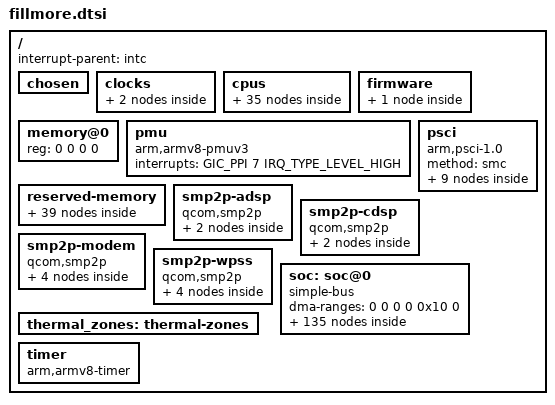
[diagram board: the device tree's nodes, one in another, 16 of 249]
// SPDX-License-Identifier: GPL-2.0-only
/*
 * Copyright (c) 2026, Aelin Reidel <aelin@mainlining.org>
 */

#include <dt-bindings/clock/qcom,dsi-phy-28nm.h>
#include <dt-bindings/clock/qcom,fillmore-dispcc.h>
#include <dt-bindings/clock/qcom,fillmore-gcc.h>
#include <dt-bindings/clock/qcom,fillmore-gpucc.h>
#include <dt-bindings/clock/qcom,rpmh.h>
#include <dt-bindings/dma/qcom-gpi.h>
#include <dt-bindings/firmware/qcom,scm.h>
#include <dt-bindings/gpio/gpio.h>
#include <dt-bindings/interrupt-controller/arm-gic.h>
#include <dt-bindings/mailbox/qcom-ipcc.h>
#include <dt-bindings/power/qcom,rpmhpd.h>
#include <dt-bindings/soc/qcom,rpmh-rsc.h>

/ {
	interrupt-parent = <&intc>;

	#address-cells = <2>;
	#size-cells = <2>;

	chosen { };

	clocks {
		xo_board: xo_board {
			compatible = "fixed-clock";
			clock-frequency = <76800000>;
			#clock-cells = <0>;
		};

		sleep_clk: sleep_clk {
			compatible = "fixed-clock";
			clock-frequency = <32000>;
			#clock-cells = <0>;
		};
	};

	cpus {
		#address-cells = <2>;
		#size-cells = <0>;

		cpu0: cpu@0 {
			device_type = "cpu";
			compatible = "qcom,kryo780";
			reg = <0x0 0x0>;

			clocks = <&cpufreq_hw 0>;

			power-domains = <&cpu_pd0>;
			power-domain-names = "psci";

			enable-method = "psci";
			next-level-cache = <&l2_0>;
			capacity-dmips-mhz = <1024>;
			dynamic-power-coefficient = <100>;

			qcom,freq-domain = <&cpufreq_hw 0>;

			#cooling-cells = <2>;

			l2_0: l2-cache {
				compatible = "cache";
				cache-level = <2>;
				cache-unified;
				next-level-cache = <&l3_0>;

				l3_0: l3-cache {
					compatible = "cache";
					cache-level = <3>;
					cache-unified;
				};
			};
		};

		cpu1: cpu@100 {
			device_type = "cpu";
			compatible = "qcom,kryo780";
			reg = <0x0 0x100>;

			clocks = <&cpufreq_hw 0>;

			power-domains = <&cpu_pd1>;
			power-domain-names = "psci";

			enable-method = "psci";
			next-level-cache = <&l2_0>;
			capacity-dmips-mhz = <1024>;
			dynamic-power-coefficient = <100>;

			qcom,freq-domain = <&cpufreq_hw 0>;

			#cooling-cells = <2>;
		};

		cpu2: cpu@200 {
			device_type = "cpu";
			compatible = "qcom,kryo780";
			reg = <0x0 0x200>;

			clocks = <&cpufreq_hw 0>;

			power-domains = <&cpu_pd2>;
			power-domain-names = "psci";

			enable-method = "psci";
			next-level-cache = <&l2_2>;
			capacity-dmips-mhz = <1024>;
			dynamic-power-coefficient = <100>;

			qcom,freq-domain = <&cpufreq_hw 0>;

			#cooling-cells = <2>;

			l2_2: l2-cache {
				compatible = "cache";
				cache-level = <2>;
				cache-unified;
				next-level-cache = <&l3_0>;
			};
		};

		cpu3: cpu@300 {
			device_type = "cpu";
			compatible = "qcom,kryo780";
			reg = <0x0 0x300>;

			clocks = <&cpufreq_hw 0>;

			power-domains = <&cpu_pd3>;
			power-domain-names = "psci";

			enable-method = "psci";
			next-level-cache = <&l2_2>;
			capacity-dmips-mhz = <1024>;
			dynamic-power-coefficient = <100>;

			qcom,freq-domain = <&cpufreq_hw 0>;

			#cooling-cells = <2>;
		};

		cpu4: cpu@400 {
			device_type = "cpu";
			compatible = "qcom,kryo780";
			reg = <0x0 0x400>;

			clocks = <&cpufreq_hw 1>;

			power-domains = <&cpu_pd4>;
			power-domain-names = "psci";

			enable-method = "psci";
			next-level-cache = <&l2_4>;
			capacity-dmips-mhz = <2253>;
			dynamic-power-coefficient = <260>;

			qcom,freq-domain = <&cpufreq_hw 1>;

			#cooling-cells = <2>;

			l2_4: l2-cache {
				compatible = "cache";
				cache-level = <2>;
				cache-unified;
				next-level-cache = <&l3_0>;
			};
		};

		cpu5: cpu@500 {
			device_type = "cpu";
			compatible = "qcom,kryo780";
			reg = <0x0 0x500>;

			clocks = <&cpufreq_hw 1>;

			power-domains = <&cpu_pd5>;
			power-domain-names = "psci";

			enable-method = "psci";
			next-level-cache = <&l2_5>;
			capacity-dmips-mhz = <2253>;
			dynamic-power-coefficient = <260>;

			qcom,freq-domain = <&cpufreq_hw 1>;

			#cooling-cells = <2>;

			l2_5: l2-cache {
				compatible = "cache";
				cache-level = <2>;
				cache-unified;
				next-level-cache = <&l3_0>;
			};
		};

		cpu6: cpu@600 {
			device_type = "cpu";
			compatible = "qcom,kryo780";
			reg = <0x0 0x600>;

			clocks = <&cpufreq_hw 1>;

			power-domains = <&cpu_pd6>;
			power-domain-names = "psci";

			enable-method = "psci";
			next-level-cache = <&l2_6>;
			capacity-dmips-mhz = <2253>;
			dynamic-power-coefficient = <260>;

			qcom,freq-domain = <&cpufreq_hw 1>;

			#cooling-cells = <2>;

			l2_6: l2-cache {
				compatible = "cache";
				cache-level = <2>;
				cache-unified;
				next-level-cache = <&l3_0>;
			};
		};

		cpu7: cpu@700 {
			device_type = "cpu";
			compatible = "qcom,kryo780";
			reg = <0x0 0x700>;

			clocks = <&cpufreq_hw 2>;

			power-domains = <&cpu_pd7>;
			power-domain-names = "psci";

			enable-method = "psci";
			next-level-cache = <&l2_7>;
			capacity-dmips-mhz = <2386>;
			dynamic-power-coefficient = <396>;

			qcom,freq-domain = <&cpufreq_hw 2>;

			#cooling-cells = <2>;

			l2_7: l2-cache {
				compatible = "cache";
				cache-level = <2>;
				cache-unified;
				next-level-cache = <&l3_0>;
			};
		};

		cpu-map {
			cluster0 {
				core0 {
					cpu = <&cpu0>;
				};

				core1 {
					cpu = <&cpu1>;
				};

				core2 {
					cpu = <&cpu2>;
				};

				core3 {
					cpu = <&cpu3>;
				};
			};

			cluster1 {
				core0 {
					cpu = <&cpu4>;
				};

				core1 {
					cpu = <&cpu5>;
				};

				core2 {
					cpu = <&cpu6>;
				};
			};

			cluster2 {
				core0 {
					cpu = <&cpu7>;
				};
			};
		};

		idle-states {
			entry-method = "psci";

			silver_cpu_sleep_0: cpu-sleep-0-0 {
				compatible = "arm,idle-state";
				idle-state-name = "pc";
				arm,psci-suspend-param = <0x40000003>;
				entry-latency-us = <350>;
				exit-latency-us = <900>;
				min-residency-us = <1774>;
				local-timer-stop;
			};

			silver_cpu_sleep_1: cpu-sleep-0-1 {
				compatible = "arm,idle-state";
				idle-state-name = "silver-rail-power-collapse";
				arm,psci-suspend-param = <0x40000004>;
				entry-latency-us = <800>;
				exit-latency-us = <750>;
				min-residency-us = <4090>;
				local-timer-stop;
			};

			gold_cpu_sleep_0: cpu-sleep-1-0 {
				compatible = "arm,idle-state";
				idle-state-name = "gold-power-collapse";
				arm,psci-suspend-param = <0x40000003>;
				entry-latency-us = <400>;
				exit-latency-us = <1550>;
				min-residency-us = <2207>;
				local-timer-stop;
			};

			gold_cpu_sleep_1: cpu-sleep-1-1 {
				compatible = "arm,idle-state";
				idle-state-name = "gold-rail-power-collapse";
				arm,psci-suspend-param = <0x40000004>;
				entry-latency-us = <600>;
				exit-latency-us = <1550>;
				min-residency-us = <4791>;
				local-timer-stop;
			};
		};

		domain-idle-states {
			cluster_sleep_0: cluster-sleep-0 {
				compatible = "domain-idle-state";
				arm,psci-suspend-param = <0x41000044>;
				entry-latency-us = <1050>;
				exit-latency-us = <2500>;
				min-residency-us = <5309>;
			};

			cluster_sleep_1: cluster-sleep-1 {
				compatible = "domain-idle-state";
				arm,psci-suspend-param = <0x4100b344>;
				entry-latency-us = <2700>;
				exit-latency-us = <3500>;
				min-residency-us = <13959>;
			};
		};
	};

	firmware {
		scm: scm {
			compatible = "qcom,scm-fillmore", "qcom,scm";
			qcom,dload-mode = <&tcsr 0x13000>;
		};
	};

	memory@0 {
		device_type = "memory";
		/* We expect the bootloader to fill in the size */
		reg = <0 0 0 0>;
	};

	pmu {
		compatible = "arm,armv8-pmuv3";
		interrupts = <GIC_PPI 7 IRQ_TYPE_LEVEL_HIGH>;
	};

	psci {
		compatible = "arm,psci-1.0";
		method = "smc";

		cpu_pd0: power-domain-cpu0 {
			#power-domain-cells = <0>;
			power-domains = <&cluster_pd>;
			domain-idle-states = <&silver_cpu_sleep_0>, <&silver_cpu_sleep_1>;
		};

		cpu_pd1: power-domain-cpu1 {
			#power-domain-cells = <0>;
			power-domains = <&cluster_pd>;
			domain-idle-states = <&silver_cpu_sleep_0>, <&silver_cpu_sleep_1>;
		};

		cpu_pd2: power-domain-cpu2 {
			#power-domain-cells = <0>;
			power-domains = <&cluster_pd>;
			domain-idle-states = <&silver_cpu_sleep_0>, <&silver_cpu_sleep_1>;
		};

		cpu_pd3: power-domain-cpu3 {
			#power-domain-cells = <0>;
			power-domains = <&cluster_pd>;
			domain-idle-states = <&silver_cpu_sleep_0>, <&silver_cpu_sleep_1>;
		};

		cpu_pd4: power-domain-cpu4 {
			#power-domain-cells = <0>;
			power-domains = <&cluster_pd>;
			domain-idle-states = <&gold_cpu_sleep_0>, <&gold_cpu_sleep_1>;
		};

		cpu_pd5: power-domain-cpu5 {
			#power-domain-cells = <0>;
			power-domains = <&cluster_pd>;
			domain-idle-states = <&gold_cpu_sleep_0>, <&gold_cpu_sleep_1>;
		};

		cpu_pd6: power-domain-cpu6 {
			#power-domain-cells = <0>;
			power-domains = <&cluster_pd>;
			domain-idle-states = <&gold_cpu_sleep_0>, <&gold_cpu_sleep_1>;
		};

		cpu_pd7: power-domain-cpu7 {
			#power-domain-cells = <0>;
			power-domains = <&cluster_pd>;
			domain-idle-states = <&gold_cpu_sleep_0>, <&gold_cpu_sleep_1>;
		};

		cluster_pd: power-domain-cluster {
			#power-domain-cells = <0>;
			domain-idle-states = <&cluster_sleep_0>, <&cluster_sleep_1>;
		};
	};

	reserved-memory {
		#address-cells = <2>;
		#size-cells = <2>;
		ranges;

		hyp_mem: hyp-region@80000000 {
			reg = <0x0 0x80000000 0x0 0x600000>;
			no-map;
		};

		xbl_dtlog_mem: xbl-dtlog-region@80600000 {
			reg = <0x0 0x80600000 0x0 0x40000>;
			no-map;
		};

		xbl_ramdump_mem: xbl-ramdump-region@80640000 {
			reg = <0x0 0x80640000 0x0 0x1c0000>;
			no-map;
		};

		aop_image_mem: aop-image-region@80800000 {
			reg = <0x0 0x80800000 0x0 0x60000>;
			no-map;
		};

		aop_cmd_db_mem: aop-cmd-db-region@80860000 {
			compatible = "qcom,cmd-db";
			reg = <0x0 0x80860000 0x0 0x20000>;
			no-map;
		};

		aop_config_mem: aop-config-region@80880000 {
			reg = <0x0 0x80880000 0x0 0x20000>;
			no-map;
		};

		tme_crash_dump_mem: tme-crash-dump-region@808a0000 {
			reg = <0x0 0x808a0000 0x0 0x40000>;
			no-map;
		};

		tme_log_mem: tme-log-region@808e0000 {
			reg = <0x0 0x808e0000 0x0 0x4000>;
			no-map;
		};

		uefi_log_mem: uefi-log-mem@808e4000 {
			reg = <0x0 0x808e4000 0x0 0x10000>;
			no-map;
		};

		smem_mem: smem-region@80900000 {
			compatible = "qcom,smem";
			reg = <0x0 0x80900000 0x0 0x200000>;
			hwlocks = <&tcsr_mutex 3>;
			no-map;
		};

		cpucp_fw_mem: cpucp-fw-region@80b00000 {
			reg = <0x0 0x80b00000 0x0 0x100000>;
			no-map;
		};

		cdsp_secure_heap_mem: cdsp-secure-heap-region@80c00000 {
			reg = <0x0 0x80c00000 0x0 0x1e00000>;
			no-map;
		};

		wlan_fw_mem: wlan-fw-region@82a00000 {
			reg = <0x0 0x82a00000 0x0 0xc00000>;
			no-map;
		};

		camera_mem: camera-region@84e00000 {
			reg = <0x0 0x84e00000 0x0 0x500000>;
			no-map;
		};

		wpss_mem: wpss-region@85300000 {
			reg = <0x0 0x85300000 0x0 0x1900000>;
			no-map;
		};

		video_mem: video-region@86c00000 {
			reg = <0x0 0x86c00000 0x0 0x700000>;
			no-map;
		};

		adsp_mem: adsp-region@87300000 {
			reg = <0x0 0x87300000 0x0 0x2800000>;
			no-map;
		};

		cdsp_mem: cdsp-region@89b00000 {
			reg = <0x0 0x89b00000 0x0 0x2000000>;
			no-map;
		};

		ipa_fw_mem: ipa-fw-region@8bb00000 {
			reg = <0x0 0x8bb00000 0x0 0x10000>;
			no-map;
		};

		ipa_gsi_mem: ipa-gsi-region@8bb10000 {
			reg = <0x0 0x8bb10000 0x0 0xa000>;
			no-map;
		};

		gpu_microcode_mem: gpu-microcode-region@8bb1a000 {
			reg = <0x0 0x8bb1a000 0x0 0x2000>;
			no-map;
		};

		mpss_mem: mpss-region@8bc00000 {
			reg = <0x0 0x8bc00000 0x0 0x13200000>;
			no-map;
		};

		cvp_mem: cvp-region@9ee00000 {
			reg = <0x0 0x9ee00000 0x0 0x500000>;
			no-map;
		};

		xbl_sc_mem: xbl-sc-region@a6e00000 {
			reg = <0x0 0xa6e00000 0x0 0x40000>;
			no-map;
		};

		global_sync_mem: global-sync-region@a6f00000 {
			reg = <0x0 0xa6f00000 0x0 0x100000>;
			no-map;
		};

		oem_vm_mem: oem-vm-region@bb000000 {
			reg = <0x0 0xbb000000 0x0 0x5000000>;
			no-map;
		};

		mte_mem: mte-region@c0000000 {
			reg = <0x0 0xc0000000 0x0 0x20000000>;
			no-map;
		};

		qheebsp_reserved_mem: qheebsp-reserved-region@e0000000 {
			reg = <0x0 0xe0000000 0x0 0x600000>;
			no-map;
		};

		cpusys_vm_mem: cpusys-vm-region@e0600000 {
			reg = <0x0 0xe0600000 0x0 0x400000>;
			no-map;
		};

		trust_ui_vm_mem: trust-ui-vm-region@e0b00000 {
			reg = <0x0 0xe0b00000 0x0 0x4af3000>;
			no-map;
		};

		trust_ui_vm_qrtr_mem: trust-ui-vm-qrtr-region@e55f3000 {
			reg = <0x0 0xe55f3000 0x0 0x9000>;
			no-map;
		};

		trust_ui_vm_vblk0_ring_mem: trust-ui-vm-vblk0-ring-region@e55fc000 {
			reg = <0x0 0xe55fc000 0x0 0x4000>;
			no-map;
		};

		trust_ui_vm_swiotlb_mem: trust-ui-vm-swiotlb-region@e5600000 {
			reg = <0x0 0xe5600000 0x0 0x100000>;
			no-map;
		};

		tz_stat_mem: tz-stat-region@e8800000 {
			reg = <0x0 0xe8800000 0x0 0x100000>;
			no-map;
		};

		tags_mem: tags-region@e8900000 {
			reg = <0x0 0xe8900000 0x0 0x1200000>;
			no-map;
		};

		qtee_mem: qtee-region@e9b00000 {
			reg = <0x0 0xe9b00000 0x0 0x500000>;
			no-map;
		};

		trusted_apps_mem: trusted-apps-region@ea000000 {
			reg = <0x0 0xea000000 0x0 0x3900000>;
			no-map;
		};

		trusted_apps_ext_mem: trusted-apps-ext-region@ed900000 {
			reg = <0x0 0xed900000 0x0 0x3b00000>;
			no-map;
		};

		rmtfs_mem: rmtfs@f7000000 {
			compatible = "qcom,rmtfs-mem";
			reg = <0x0 0xf7000000 0x0 0x280000>;
			no-map;

			qcom,client-id = <1>;
			qcom,vmid = <QCOM_SCM_VMID_MSS_MSA>;
		};
	};

	smp2p-adsp {
		compatible = "qcom,smp2p";
		qcom,smem = <443>, <429>;
		interrupts-extended = <&ipcc IPCC_CLIENT_LPASS
					     IPCC_MPROC_SIGNAL_SMP2P
					     IRQ_TYPE_EDGE_RISING>;
		mboxes = <&ipcc IPCC_CLIENT_LPASS
				IPCC_MPROC_SIGNAL_SMP2P>;

		qcom,local-pid = <0>;
		qcom,remote-pid = <2>;


		smp2p_adsp_out: master-kernel {
			qcom,entry-name = "master-kernel";
			#qcom,smem-state-cells = <1>;
		};

		smp2p_adsp_in: slave-kernel {
			qcom,entry-name = "slave-kernel";
			interrupt-controller;
			#interrupt-cells = <2>;
		};
	};

	smp2p-cdsp {
		compatible = "qcom,smp2p";
		qcom,smem = <94>, <432>;
		interrupts-extended = <&ipcc IPCC_CLIENT_CDSP
					     IPCC_MPROC_SIGNAL_SMP2P
					     IRQ_TYPE_EDGE_RISING>;
		mboxes = <&ipcc IPCC_CLIENT_CDSP
				IPCC_MPROC_SIGNAL_SMP2P>;

		qcom,local-pid = <0>;
		qcom,remote-pid = <5>;

		smp2p_cdsp_out: master-kernel {
			qcom,entry-name = "master-kernel";
			#qcom,smem-state-cells = <1>;
		};

		smp2p_cdsp_in: slave-kernel {
			qcom,entry-name = "slave-kernel";
			interrupt-controller;
			#interrupt-cells = <2>;
		};
	};

	smp2p-modem {
		compatible = "qcom,smp2p";
		qcom,smem = <435>, <428>;
		interrupts-extended = <&ipcc IPCC_CLIENT_MPSS
					     IPCC_MPROC_SIGNAL_SMP2P
					     IRQ_TYPE_EDGE_RISING>;
		mboxes = <&ipcc IPCC_CLIENT_MPSS
				IPCC_MPROC_SIGNAL_SMP2P>;

		qcom,local-pid = <0>;
		qcom,remote-pid = <1>;

		smp2p_modem_out: master-kernel {
			qcom,entry-name = "master-kernel";
			#qcom,smem-state-cells = <1>;
		};

		smp2p_modem_in: slave-kernel {
			qcom,entry-name = "slave-kernel";
			interrupt-controller;
			#interrupt-cells = <2>;
		};

		smp2p_ipa_out: ipa-ap-to-modem {
			qcom,entry-name = "ipa";
			#qcom,smem-state-cells = <1>;
		};

		smp2p_ipa_in: ipa-modem-to-ap {
			qcom,entry-name = "ipa";
			interrupt-controller;
			#interrupt-cells = <2>;
		};
	};

	smp2p-wpss {
		compatible = "qcom,smp2p";
		qcom,smem = <617>, <616>;
		interrupts-extended = <&ipcc IPCC_CLIENT_WPSS
					     IPCC_MPROC_SIGNAL_SMP2P
					     IRQ_TYPE_EDGE_RISING>;
		mboxes = <&ipcc IPCC_CLIENT_WPSS
				IPCC_MPROC_SIGNAL_SMP2P>;

		qcom,local-pid = <0>;
		qcom,remote-pid = <13>;

		smp2p_wpss_out: master-kernel {
			qcom,entry-name = "master-kernel";
			#qcom,smem-state-cells = <1>;
		};

		smp2p_wpss_in: slave-kernel {
			qcom,entry-name = "slave-kernel";
			interrupt-controller;
			#interrupt-cells = <2>;
		};

		smp2p_wlan_out: wlan-ap-to-wpss {
			qcom,entry-name = "wlan";
			#qcom,smem-state-cells = <1>;
		};

		smp2p_wlan_in: wlan-wpss-to-ap {
			qcom,entry-name = "wlan";
			interrupt-controller;
			#interrupt-cells = <2>;
		};
	};

	soc: soc@0 {
		compatible = "simple-bus";

		#address-cells = <2>;
		#size-cells = <2>;
		dma-ranges = <0 0 0 0 0x10 0>;
		ranges = <0 0 0 0 0x10 0>;

		gcc: clock-controller@100000 {
			compatible = "qcom,fillmore-gcc";
			reg = <0x0 0x00100000 0x0 0x1f4200>;

			clocks = <&rpmhcc RPMH_CXO_CLK>,
				 <&sleep_clk>,
				 <0>, /* pcie_0_pipe_clk */
				 <&ufs_mem_phy 0>,
				 <&ufs_mem_phy 1>,
				 <&ufs_mem_phy 2>,
				 <0>; /* usb3_phy_wrapper_gcc_usb30_pipe_clk */

			#clock-cells = <1>;
			#reset-cells = <1>;
			#power-domain-cells = <1>;
		};

		gpi_dma0: dma-controller@900000 {
			compatible = "qcom,fillmore-gpi-dma", "qcom,sm6350-gpi-dma";
			reg = <0x0 0x00900000 0x0 0x60000>;

			interrupts = <GIC_SPI 244 IRQ_TYPE_LEVEL_HIGH>,
				     <GIC_SPI 245 IRQ_TYPE_LEVEL_HIGH>,
				     <GIC_SPI 246 IRQ_TYPE_LEVEL_HIGH>,
				     <GIC_SPI 247 IRQ_TYPE_LEVEL_HIGH>,
				     <GIC_SPI 248 IRQ_TYPE_LEVEL_HIGH>,
				     <GIC_SPI 249 IRQ_TYPE_LEVEL_HIGH>,
				     <GIC_SPI 250 IRQ_TYPE_LEVEL_HIGH>,
				     <GIC_SPI 251 IRQ_TYPE_LEVEL_HIGH>,
				     <GIC_SPI 252 IRQ_TYPE_LEVEL_HIGH>,
				     <GIC_SPI 253 IRQ_TYPE_LEVEL_HIGH>,
				     <GIC_SPI 254 IRQ_TYPE_LEVEL_HIGH>,
				     <GIC_SPI 255 IRQ_TYPE_LEVEL_HIGH>;

			dma-channels = <12>;
			dma-channel-mask = <0x7e>;
			#dma-cells = <3>;

			iommus = <&apps_smmu 0x536 0x0>;
			dma-coherent;
		};

		qupv3_id_0: geniqup@9c0000 {
			compatible = "qcom,geni-se-qup";
			reg = <0x0 0x009c0000 0x0 0x2000>;

			clocks = <&gcc GCC_QUPV3_WRAP_0_M_AHB_CLK>,
				 <&gcc GCC_QUPV3_WRAP_0_S_AHB_CLK>;
			clock-names = "m-ahb",
				      "s-ahb";

			iommus = <&apps_smmu 0x523 0>;

			dma-coherent;

			#address-cells = <2>;
			#size-cells = <2>;
			ranges;

			status = "disabled";

			spi0: spi@980000 {
				compatible = "qcom,geni-spi";
				reg = <0x0 0x00980000 0x0 0x4000>;

				interrupts = <GIC_SPI 601 IRQ_TYPE_LEVEL_HIGH>;

				clocks = <&gcc GCC_QUPV3_WRAP0_S0_CLK>;
				clock-names = "se";

				dmas = <&gpi_dma0 0 0 QCOM_GPI_SPI>,
				       <&gpi_dma0 1 0 QCOM_GPI_SPI>;
				dma-names = "tx",
					    "rx";

				pinctrl-0 = <&qup_spi0_data_clk>, <&qup_spi0_cs>;
				pinctrl-names = "default";

				#address-cells = <1>;
				#size-cells = <0>;

				status = "disabled";
			};

			i2c1: i2c@984000 {
				compatible = "qcom,geni-i2c";
				reg = <0x0 0x00984000 0x0 0x4000>;

				interrupts = <GIC_SPI 602 IRQ_TYPE_LEVEL_HIGH>;

				clocks = <&gcc GCC_QUPV3_WRAP0_S1_CLK>;
				clock-names = "se";

				dmas = <&gpi_dma0 0 1 QCOM_GPI_I2C>,
				       <&gpi_dma0 1 1 QCOM_GPI_I2C>;
				dma-names = "tx",
					    "rx";

				pinctrl-0 = <&qup_i2c1_data_clk>;
				pinctrl-names = "default";

				#address-cells = <1>;
				#size-cells = <0>;

				status = "disabled";
			};

			i2c2: i2c@988000 {
				compatible = "qcom,geni-i2c";
				reg = <0x0 0x00988000 0x0 0x4000>;

				interrupts = <GIC_SPI 603 IRQ_TYPE_LEVEL_HIGH>;

				clocks = <&gcc GCC_QUPV3_WRAP0_S2_CLK>;
				clock-names = "se";

				dmas = <&gpi_dma0 0 2 QCOM_GPI_I2C>,
				       <&gpi_dma0 1 2 QCOM_GPI_I2C>;
				dma-names = "tx",
					    "rx";

				pinctrl-0 = <&qup_i2c2_data_clk>;
				pinctrl-names = "default";

				#address-cells = <1>;
				#size-cells = <0>;

				status = "disabled";
			};

			i2c3: i2c@98c000 {
				compatible = "qcom,geni-i2c";
				reg = <0x0 0x0098c000 0x0 0x4000>;

				interrupts = <GIC_SPI 604 IRQ_TYPE_LEVEL_HIGH>;

				clocks = <&gcc GCC_QUPV3_WRAP0_S3_CLK>;
				clock-names = "se";

				dmas = <&gpi_dma0 0 3 QCOM_GPI_I2C>,
				       <&gpi_dma0 1 3 QCOM_GPI_I2C>;
				dma-names = "tx",
					    "rx";

				pinctrl-0 = <&qup_i2c3_data_clk>;
				pinctrl-names = "default";

				#address-cells = <1>;
				#size-cells = <0>;

				status = "disabled";
			};

			i2c4: i2c@990000 {
				compatible = "qcom,geni-i2c";
				reg = <0x0 0x00990000 0x0 0x4000>;

				interrupts = <GIC_SPI 605 IRQ_TYPE_LEVEL_HIGH>;

				clocks = <&gcc GCC_QUPV3_WRAP0_S4_CLK>;
				clock-names = "se";

				dmas = <&gpi_dma0 0 4 QCOM_GPI_I2C>,
				       <&gpi_dma0 1 4 QCOM_GPI_I2C>;
				dma-names = "tx",
					    "rx";

				pinctrl-0 = <&qup_i2c4_data_clk>;
				pinctrl-names = "default";

				#address-cells = <1>;
				#size-cells = <0>;

				status = "disabled";
			};

			uart5: serial@994000 {
				compatible = "qcom,geni-debug-uart";
				reg = <0x0 0x00994000 0x0 0x4000>;

				interrupts = <GIC_SPI 606 IRQ_TYPE_LEVEL_HIGH>;

				clocks = <&gcc GCC_QUPV3_WRAP0_S5_CLK>;
				clock-names = "se";

				pinctrl-0 = <&qup_uart5_default>;
				pinctrl-names = "default";

				status = "disabled";
			};

			uart7: serial@99c000 {
				compatible = "qcom,geni-uart";
				reg = <0x0 0x0099c000 0x0 0x4000>;

				interrupts = <GIC_SPI 608 IRQ_TYPE_LEVEL_HIGH>;

				clocks = <&gcc GCC_QUPV3_WRAP0_S7_CLK>;
				clock-names = "se";

				pinctrl-0 = <&qup_uart7_cts>, <&qup_uart7_rts>,
					    <&qup_uart7_tx>, <&qup_uart7_rx>;
				pinctrl-names = "default";

				status = "disabled";
			};
		};

		gpi_dma1: dma-controller@a00000 {
			compatible = "qcom,fillmore-gpi-dma", "qcom,sm6350-gpi-dma";
			reg = <0x0 0x00a00000 0x0 0x60000>;

			interrupts = <GIC_SPI 279 IRQ_TYPE_LEVEL_HIGH>,
				     <GIC_SPI 280 IRQ_TYPE_LEVEL_HIGH>,
				     <GIC_SPI 281 IRQ_TYPE_LEVEL_HIGH>,
				     <GIC_SPI 282 IRQ_TYPE_LEVEL_HIGH>,
				     <GIC_SPI 283 IRQ_TYPE_LEVEL_HIGH>,
				     <GIC_SPI 284 IRQ_TYPE_LEVEL_HIGH>,
				     <GIC_SPI 293 IRQ_TYPE_LEVEL_HIGH>,
				     <GIC_SPI 294 IRQ_TYPE_LEVEL_HIGH>,
				     <GIC_SPI 295 IRQ_TYPE_LEVEL_HIGH>,
				     <GIC_SPI 296 IRQ_TYPE_LEVEL_HIGH>,
				     <GIC_SPI 297 IRQ_TYPE_LEVEL_HIGH>,
				     <GIC_SPI 298 IRQ_TYPE_LEVEL_HIGH>;

			dma-channels = <12>;
			dma-channel-mask = <0x6f>;
			#dma-cells = <3>;

			iommus = <&apps_smmu 0x16 0x0>;
			dma-coherent;
		};

		qupv3_id_1: geniqup@ac0000 {
			compatible = "qcom,geni-se-qup";
			reg = <0x0 0x00ac0000 0x0 0x2000>;

			clocks = <&gcc GCC_QUPV3_WRAP_1_M_AHB_CLK>,
				 <&gcc GCC_QUPV3_WRAP_1_S_AHB_CLK>;
			clock-names = "m-ahb",
				      "s-ahb";

			iommus = <&apps_smmu 0x3 0>;

			dma-coherent;

			#address-cells = <2>;
			#size-cells = <2>;
			ranges;

			status = "disabled";

			i2c9: i2c@a84000 {
				compatible = "qcom,geni-i2c";
				reg = <0x0 0x00a84000 0x0 0x4000>;

				interrupts = <GIC_SPI 354 IRQ_TYPE_LEVEL_HIGH>;

				clocks = <&gcc GCC_QUPV3_WRAP1_S1_CLK>;
				clock-names = "se";

				dmas = <&gpi_dma1 0 1 QCOM_GPI_I2C>,
				       <&gpi_dma1 1 1 QCOM_GPI_I2C>;
				dma-names = "tx",
					    "rx";

				pinctrl-0 = <&qup_i2c9_data_clk>;
				pinctrl-names = "default";

				#address-cells = <1>;
				#size-cells = <0>;

				status = "disabled";
			};

			spi11: spi@a8c000 {
				compatible = "qcom,geni-spi";
				reg = <0x0 0x00a8c000 0x0 0x4000>;

				interrupts = <GIC_SPI 356 IRQ_TYPE_LEVEL_HIGH>;

				clocks = <&gcc GCC_QUPV3_WRAP1_S3_CLK>;
				clock-names = "se";

				dmas = <&gpi_dma1 0 3 QCOM_GPI_SPI>,
				       <&gpi_dma1 1 3 QCOM_GPI_SPI>;
				dma-names = "tx",
					    "rx";

				pinctrl-0 = <&qup_spi11_data_clk>, <&qup_spi11_cs>;
				pinctrl-names = "default";

				#address-cells = <1>;
				#size-cells = <0>;

				status = "disabled";
			};

			i2c12: i2c@a90000 {
				compatible = "qcom,geni-i2c";
				reg = <0x0 0x00a90000 0x0 0x4000>;

				interrupts = <GIC_SPI 357 IRQ_TYPE_LEVEL_HIGH>;

				clocks = <&gcc GCC_QUPV3_WRAP1_S4_CLK>;
				clock-names = "se";

				dmas = <&gpi_dma1 0 4 QCOM_GPI_I2C>,
				       <&gpi_dma1 1 4 QCOM_GPI_I2C>;
				dma-names = "tx",
					    "rx";

				pinctrl-0 = <&qup_i2c12_data_clk>;
				pinctrl-names = "default";

				#address-cells = <1>;
				#size-cells = <0>;

				status = "disabled";
			};

			i2c13: i2c@a94000 {
				compatible = "qcom,geni-i2c";
				reg = <0x0 0x00a94000 0x0 0x4000>;

				interrupts = <GIC_SPI 358 IRQ_TYPE_LEVEL_HIGH>;

				clocks = <&gcc GCC_QUPV3_WRAP1_S5_CLK>;
				clock-names = "se";

				dmas = <&gpi_dma1 0 5 QCOM_GPI_I2C>,
				       <&gpi_dma1 1 5 QCOM_GPI_I2C>;
				dma-names = "tx",
					    "rx";

				pinctrl-0 = <&qup_i2c13_data_clk>;
				pinctrl-names = "default";

				#address-cells = <1>;
				#size-cells = <0>;

				status = "disabled";
			};
		};


		rng: rng@10c3000 {
			compatible = "qcom,fillmore-trng", "qcom,trng";
			reg = <0x0 0x010c3000 0x0 0x1000>;
		};

		ufs_mem_hc: ufshc@1d84000 {
			compatible = "qcom,fillmore-ufshc",
				     "qcom,ufshc",
				     "jedec,ufs-2.0";
			reg = <0x0 0x01d84000 0x0 0x3000>;

			interrupts = <GIC_SPI 265 IRQ_TYPE_LEVEL_HIGH>;

			clock-names = "core_clk",
				      "bus_aggr_clk",
				      "iface_clk",
				      "core_clk_unipro",
				      "ref_clk",
				      "tx_lane0_sync_clk",
				      "rx_lane0_sync_clk",
				      "rx_lane1_sync_clk";
			clocks = <&gcc GCC_UFS_PHY_AXI_CLK>,
				 <&gcc GCC_AGGRE_UFS_PHY_AXI_CLK>,
				 <&gcc GCC_UFS_PHY_AHB_CLK>,
				 <&gcc GCC_UFS_PHY_UNIPRO_CORE_CLK>,
				 <&rpmhcc RPMH_CXO_CLK>,
				 <&gcc GCC_UFS_PHY_TX_SYMBOL_0_CLK>,
				 <&gcc GCC_UFS_PHY_RX_SYMBOL_0_CLK>,
				 <&gcc GCC_UFS_PHY_RX_SYMBOL_1_CLK>;

			resets = <&gcc GCC_UFS_PHY_BCR>;
			reset-names = "rst";

			power-domains = <&gcc GCC_UFS_PHY_GDSC>;
			required-opps = <&rpmhpd_opp_nom>;

			operating-points-v2 = <&ufs_opp_table>;

			iommus = <&apps_smmu 0x20 0x0>;

			dma-coherent;

			lanes-per-direction = <2>;
			qcom,ice = <&ice>;

			phys = <&ufs_mem_phy>;
			phy-names = "ufsphy";

			#reset-cells = <1>;

			status = "disabled";

			ufs_opp_table: opp-table {
				compatible = "operating-points-v2";

				opp-75000000 {
					opp-hz = /bits/ 64 <75000000>,
						 /bits/ 64 <0>,
						 /bits/ 64 <0>,
						 /bits/ 64 <75000000>,
						 /bits/ 64 <0>,
						 /bits/ 64 <0>,
						 /bits/ 64 <0>,
						 /bits/ 64 <0>;
					required-opps = <&rpmhpd_opp_low_svs>;
				};

				opp-150000000 {
					opp-hz = /bits/ 64 <150000000>,
						 /bits/ 64 <0>,
						 /bits/ 64 <0>,
						 /bits/ 64 <150000000>,
						 /bits/ 64 <0>,
						 /bits/ 64 <0>,
						 /bits/ 64 <0>,
						 /bits/ 64 <0>;
					required-opps = <&rpmhpd_opp_svs>;
				};

				opp-300000000 {
					opp-hz = /bits/ 64 <300000000>,
						 /bits/ 64 <0>,
						 /bits/ 64 <0>,
						 /bits/ 64 <300000000>,
						 /bits/ 64 <0>,
						 /bits/ 64 <0>,
						 /bits/ 64 <0>,
						 /bits/ 64 <0>;
					required-opps = <&rpmhpd_opp_nom>;
				};
			};
		};

		ufs_mem_phy: phy@1d87000 {
			compatible = "qcom,fillmore-qmp-ufs-phy";
			reg = <0x0 0x01d87000 0x0 0x1000>;

			clocks = <&rpmhcc RPMH_CXO_CLK>,
				 <&gcc GCC_UFS_PHY_PHY_AUX_CLK>,
				 <&gcc GCC_UFS_0_CLKREF_EN>;
			clock-names = "ref",
				      "ref_aux",
				      "qref";

			resets = <&ufs_mem_hc 0>;
			reset-names = "ufsphy";

			power-domains = <&gcc GCC_UFS_PHY_GDSC>;

			#clock-cells = <1>;
			#phy-cells = <0>;

			status = "disabled";
		};

		ice: crypto@1d88000 {
			compatible = "qcom,fillmore-inline-crypto-engine",
				     "qcom,inline-crypto-engine";
			reg = <0x0 0x01d88000 0x0 0x18000>;

			clocks = <&gcc GCC_UFS_PHY_ICE_CORE_CLK>;
		};

		tcsr_mutex: hwlock@1f40000 {
			compatible = "qcom,tcsr-mutex";
			reg = <0x0 0x01f40000 0x0 0x40000>;

			#hwlock-cells = <1>;
		};

		tcsr: syscon@1fc0000 {
			compatible = "qcom,fillmore-tcsr", "syscon";
			reg = <0x0 0x1fc0000 0x0 0x30000>;
		};

		remoteproc_adsp: remoteproc@3000000 {
			compatible = "qcom,fillmore-adsp-pas";
			reg = <0x0 0x03000000 0x0 0x10000>;

			interrupts-extended = <&pdc 6 IRQ_TYPE_EDGE_RISING>,
					      <&smp2p_adsp_in 0 IRQ_TYPE_EDGE_RISING>,
					      <&smp2p_adsp_in 1 IRQ_TYPE_EDGE_RISING>,
					      <&smp2p_adsp_in 2 IRQ_TYPE_EDGE_RISING>,
					      <&smp2p_adsp_in 3 IRQ_TYPE_EDGE_RISING>,
					      <&smp2p_adsp_in 7 IRQ_TYPE_EDGE_RISING>;
			interrupt-names = "wdog",
					  "fatal",
					  "ready",
					  "handover",
					  "stop-ack",
					  "shutdown-ack";

			clocks = <&rpmhcc RPMH_CXO_CLK>;
			clock-names = "xo";

			power-domains = <&rpmhpd RPMHPD_LCX>,
					<&rpmhpd RPMHPD_LMX>;
			power-domain-names = "lcx",
					     "lmx";

			memory-region = <&adsp_mem>;

			qcom,qmp = <&aoss_qmp>;

			qcom,smem-states = <&smp2p_adsp_out 0>;
			qcom,smem-state-names = "stop";

			status = "disabled";

			glink-edge {
				interrupts-extended = <&ipcc IPCC_CLIENT_LPASS
							     IPCC_MPROC_SIGNAL_GLINK_QMP
							     IRQ_TYPE_EDGE_RISING>;
				mboxes = <&ipcc IPCC_CLIENT_LPASS
						IPCC_MPROC_SIGNAL_GLINK_QMP>;

				label = "lpass";
				qcom,remote-pid = <2>;
			};
		};

		gpu: gpu@3d00000 {
			compatible = "qcom,adreno-662.1", "qcom,adreno";
			reg = <0x0 0x03d00000 0x0 0x40000>,
			      <0x0 0x03d9e000 0x0 0x1000>,
			      <0x0 0x03d61000 0x0 0x800>;
			reg-names = "kgsl_3d0_reg_memory",
				    "cx_mem",
				    "cx_dbgc";

			interrupts = <GIC_SPI 300 IRQ_TYPE_LEVEL_HIGH>;

			iommus = <&adreno_smmu 0 0x400>,
				 <&adreno_smmu 1 0x400>;

			operating-points-v2 = <&gpu_opp_table>;

			qcom,gmu = <&gmu>;
			#cooling-cells = <2>;

			nvmem-cells = <&gpu_speed_bin>;
			nvmem-cell-names = "speed_bin";

			status = "disabled";

			gpu_zap_shader: zap-shader {
				memory-region = <&gpu_microcode_mem>;
			};

			gpu_opp_table: opp-table {
				compatible = "operating-points-v2";

				opp-750000000 {
					opp-hz = /bits/ 64 <750000000>;
					opp-level = <RPMH_REGULATOR_LEVEL_NOM_L1>;
					opp-supported-hw = <0xf>;
				};

				opp-676000000 {
					opp-hz = /bits/ 64 <676000000>;
					opp-level = <RPMH_REGULATOR_LEVEL_NOM>;
					opp-supported-hw = <0xf>;
				};

				opp-608000000 {
					opp-hz = /bits/ 64 <608000000>;
					opp-level = <RPMH_REGULATOR_LEVEL_SVS_L2>;
					opp-supported-hw = <0xf>;
				};

				opp-540000000 {
					opp-hz = /bits/ 64 <540000000>;
					opp-level = <RPMH_REGULATOR_LEVEL_SVS_L1>;
					opp-supported-hw = <0xf>;
				};

				opp-443000000 {
					opp-hz = /bits/ 64 <443000000>;
					opp-level = <RPMH_REGULATOR_LEVEL_SVS>;
					opp-supported-hw = <0xf>;
				};

				opp-285000000 {
					opp-hz = /bits/ 64 <285000000>;
					opp-level = <RPMH_REGULATOR_LEVEL_LOW_SVS>;
					opp-supported-hw = <0xf>;
				};

				opp-230000000 {
					opp-hz = /bits/ 64 <230000000>;
					opp-level = <RPMH_REGULATOR_LEVEL_LOW_SVS_D1>;
					opp-supported-hw = <0xf>;
				};
			};
		};

		gmu: gmu@3d6a000 {
			compatible = "qcom,adreno-gmu-662.1", "qcom,adreno-gmu";
			reg = <0x0 0x03d6a000 0x0 0x34000>,
			      <0x0 0x03de0000 0x0 0x10000>,
			      <0x0 0x0b290000 0x0 0x10000>;
			reg-names = "gmu", "rscc", "gmu_pdc";

			interrupts = <GIC_SPI 304 IRQ_TYPE_LEVEL_HIGH>,
				     <GIC_SPI 305 IRQ_TYPE_LEVEL_HIGH>;
			interrupt-names = "hfi", "gmu";

			clocks = <&gpucc GPU_CC_AHB_CLK>,
				 <&gpucc GPU_CC_CX_GMU_CLK>,
				 <&gpucc GPU_CC_CXO_CLK>,
				 <&gcc GCC_DDRSS_GPU_AXI_CLK>,
				 <&gcc GCC_GPU_MEMNOC_GFX_CLK>,
				 <&gpucc GPU_CC_HUB_CX_INT_CLK>,
				 <&gpucc GPU_CC_HLOS1_VOTE_GPU_SMMU_CLK>;
			clock-names = "ahb",
				      "gmu",
				      "cxo",
				      "axi",
				      "memnoc",
				      "hub",
				      "smmu_vote";

			power-domains = <&gpucc GPU_CC_CX_GDSC>,
					<&gpucc GPU_CC_GX_GDSC>;
			power-domain-names = "cx",
					     "gx";

			iommus = <&adreno_smmu 5 0x400>;

			qcom,qmp = <&aoss_qmp>;

			operating-points-v2 = <&gmu_opp_table>;

			gmu_opp_table: opp-table {
				compatible = "operating-points-v2";

				opp-500000000 {
					opp-hz = /bits/ 64 <500000000>;
					opp-level = <RPMH_REGULATOR_LEVEL_SVS>;
				};
			};
		};

		gpucc: clock-controller@3d90000 {
			compatible = "qcom,fillmore-gpucc";
			reg = <0x0 0x03d90000 0x0 0xa000>;

			clocks = <&rpmhcc RPMH_CXO_CLK>,
				 <&gcc GCC_GPU_GPLL0_CLK_SRC>,
				 <&gcc GCC_GPU_GPLL0_DIV_CLK_SRC>;

			#clock-cells = <1>;
			#reset-cells = <1>;
			#power-domain-cells = <1>;
		};

		adreno_smmu: iommu@3da0000 {
			compatible = "qcom,fillmore-smmu-500", "qcom,adreno-smmu",
				     "qcom,smmu-500", "arm,mmu-500";
			reg = <0x0 0x03da0000 0x0 0x20000>;

			#iommu-cells = <2>;
			#global-interrupts = <1>;
			interrupts = <GIC_SPI 673 IRQ_TYPE_LEVEL_HIGH>,
				     <GIC_SPI 678 IRQ_TYPE_LEVEL_HIGH>,
				     <GIC_SPI 679 IRQ_TYPE_LEVEL_HIGH>,
				     <GIC_SPI 680 IRQ_TYPE_LEVEL_HIGH>,
				     <GIC_SPI 681 IRQ_TYPE_LEVEL_HIGH>,
				     <GIC_SPI 682 IRQ_TYPE_LEVEL_HIGH>,
				     <GIC_SPI 683 IRQ_TYPE_LEVEL_HIGH>,
				     <GIC_SPI 684 IRQ_TYPE_LEVEL_HIGH>,
				     <GIC_SPI 685 IRQ_TYPE_LEVEL_HIGH>,
				     <GIC_SPI 686 IRQ_TYPE_LEVEL_HIGH>,
				     <GIC_SPI 687 IRQ_TYPE_LEVEL_HIGH>;
			clocks = <&gpucc GPU_CC_CX_GMU_CLK>,
				 <&gpucc GPU_CC_HUB_CX_INT_CLK>,
				 <&gpucc GPU_CC_HUB_AON_CLK>,
				 <&gpucc GPU_CC_HLOS1_VOTE_GPU_SMMU_CLK>,
				 <&gcc GCC_GPU_MEMNOC_GFX_CLK>,
				 <&gcc GCC_GPU_SNOC_DVM_GFX_CLK>,
				 <&gpucc GPU_CC_AHB_CLK>;
			clock-names = "gmu",
				      "hub_cx_int",
				      "hub_aon",
				      "hlos",
				      "bus",
				      "iface",
				      "ahb";
			power-domains = <&gpucc GPU_CC_CX_GDSC>;
			dma-coherent;
		};

		remoteproc_mpss: remoteproc@4080000 {
			compatible = "qcom,fillmore-mpss-pas";
			reg = <0x0 0x04080000 0x0 0x10000>;

			interrupts-extended = <&intc GIC_SPI 264 IRQ_TYPE_EDGE_RISING>,
					      <&smp2p_modem_in 0 IRQ_TYPE_EDGE_RISING>,
					      <&smp2p_modem_in 1 IRQ_TYPE_EDGE_RISING>,
					      <&smp2p_modem_in 2 IRQ_TYPE_EDGE_RISING>,
					      <&smp2p_modem_in 3 IRQ_TYPE_EDGE_RISING>,
					      <&smp2p_modem_in 7 IRQ_TYPE_EDGE_RISING>;
			interrupt-names = "wdog",
					  "fatal",
					  "ready",
					  "handover",
					  "stop-ack",
					  "shutdown-ack";

			clocks = <&rpmhcc RPMH_CXO_CLK>;
			clock-names = "xo";

			power-domains = <&rpmhpd RPMHPD_CX>,
					<&rpmhpd RPMHPD_MSS>;
			power-domain-names = "cx",
					     "mss";

			memory-region = <&mpss_mem>;

			qcom,qmp = <&aoss_qmp>;

			qcom,smem-states = <&smp2p_modem_out 0>;
			qcom,smem-state-names = "stop";

			status = "disabled";

			glink-edge {
				interrupts-extended = <&ipcc IPCC_CLIENT_MPSS
							     IPCC_MPROC_SIGNAL_GLINK_QMP
							     IRQ_TYPE_EDGE_RISING>;
				mboxes = <&ipcc IPCC_CLIENT_MPSS
						IPCC_MPROC_SIGNAL_GLINK_QMP>;

				label = "mpss";
				qcom,remote-pid = <1>;
			};
		};

		usb_1_hsphy: phy@88e3000 {
			compatible = "qcom,fillmore-usb-hs-phy",
				     "qcom,usb-snps-hs-7nm-phy";
			reg = <0x0 0x088e3000 0x0 0x400>;
			#phy-cells = <0>;

			clocks = <&rpmhcc RPMH_CXO_CLK>;
			clock-names = "ref";

			resets = <&gcc GCC_QUSB2PHY_PRIM_BCR>;

			status = "disabled";
		};

		remoteproc_wpss: remoteproc@8a00000 {
			compatible = "qcom,fillmore-wpss-pas";
			reg = <0x0 0x08a00000 0x0 0x10000>;

			interrupts-extended = <&intc GIC_SPI 587 IRQ_TYPE_EDGE_RISING>,
					      <&smp2p_wpss_in 0 IRQ_TYPE_EDGE_RISING>,
					      <&smp2p_wpss_in 1 IRQ_TYPE_EDGE_RISING>,
					      <&smp2p_wpss_in 2 IRQ_TYPE_EDGE_RISING>,
					      <&smp2p_wpss_in 3 IRQ_TYPE_EDGE_RISING>;
			interrupt-names = "wdog",
					  "fatal",
					  "ready",
					  "handover",
					  "stop-ack";

			clocks = <&rpmhcc RPMH_CXO_CLK>;
			clock-names = "xo";

			power-domains = <&rpmhpd RPMHPD_CX>,
					<&rpmhpd RPMHPD_MX>;
			power-domain-names = "cx",
					     "mx";

			memory-region = <&wpss_mem>;

			qcom,qmp = <&aoss_qmp>;

			qcom,smem-states = <&smp2p_wpss_out 0>;
			qcom,smem-state-names = "stop";

			status = "disabled";

			glink-edge {
				interrupts-extended = <&ipcc IPCC_CLIENT_WPSS
							     IPCC_MPROC_SIGNAL_GLINK_QMP
							     IRQ_TYPE_EDGE_RISING>;
				mboxes = <&ipcc IPCC_CLIENT_WPSS
						IPCC_MPROC_SIGNAL_GLINK_QMP>;

				label = "wpss";
				qcom,remote-pid = <13>;
			};
		};

		usb_1: usb@a600000 {
			compatible = "qcom,fillmore-dwc3", "qcom,snps-dwc3";
			reg = <0x0 0x0a600000 0x0 0xfc100>;

			clocks = <&gcc GCC_CFG_NOC_USB3_PRIM_AXI_CLK>,
				 <&gcc GCC_USB30_PRIM_MASTER_CLK>,
				 <&gcc GCC_AGGRE_USB3_PRIM_AXI_CLK>,
				 <&gcc GCC_USB30_PRIM_SLEEP_CLK>,
				 <&gcc GCC_USB30_PRIM_MOCK_UTMI_CLK>,
				 <&gcc GCC_USB3_0_CLKREF_EN>;
			clock-names = "cfg_noc",
				      "core",
				      "iface",
				      "sleep",
				      "mock_utmi",
				      "xo";

			assigned-clocks = <&gcc GCC_USB30_PRIM_MOCK_UTMI_CLK>,
					  <&gcc GCC_USB30_PRIM_MASTER_CLK>;
			assigned-clock-rates = <19200000>, <200000000>;

			interrupts-extended = <&intc GIC_SPI 133 IRQ_TYPE_LEVEL_HIGH>,
					      <&intc GIC_SPI 130 IRQ_TYPE_LEVEL_HIGH>,
					      <&intc GIC_SPI 131 IRQ_TYPE_LEVEL_HIGH>,
					      <&pdc 14 IRQ_TYPE_EDGE_BOTH>,
					      <&pdc 15 IRQ_TYPE_EDGE_BOTH>,
					      <&pdc 17 IRQ_TYPE_LEVEL_HIGH>;
			interrupt-names = "dwc_usb3",
					  "pwr_event",
					  "hs_phy_irq",
					  "dp_hs_phy_irq",
					  "dm_hs_phy_irq",
					  "ss_phy_irq";

			iommus = <&apps_smmu 0x40 0x0>;
			power-domains = <&gcc GCC_USB30_PRIM_GDSC>;

			resets = <&gcc GCC_USB30_PRIM_BCR>;

			phys = <&usb_1_hsphy>;
			phy-names = "usb2-phy";

			snps,dis-u1-entry-quirk;
			snps,dis-u2-entry-quirk;
			snps,dis_enblslpm_quirk;
			snps,dis_u2_susphy_quirk;
			snps,dis_u3_susphy_quirk;
			snps,has-lpm-erratum;
			snps,hird-threshold = /bits/ 8 <0x0>;
			snps,is-utmi-l1-suspend;
			tx-fifo-resize;
			dma-coherent;
			usb-role-switch;

			status = "disabled";

			ports {
				#address-cells = <1>;
				#size-cells = <0>;

				port@0 {
					reg = <0>;

					usb_1_dwc3_hs: endpoint {
					};
				};
			};
		};

		mdss: display-subsystem@ae00000 {
			compatible = "qcom,fillmore-mdss";
			reg = <0x0 0x0ae00000 0x0 0x1000>;
			reg-names = "mdss";

			interrupts = <GIC_SPI 83 IRQ_TYPE_LEVEL_HIGH>;

			clocks = <&dispcc DISP_CC_MDSS_AHB_CLK>,
				 <&gcc GCC_DISP_HF_AXI_CLK>,
				 <&gcc GCC_DISP_SF_AXI_CLK>,
				 <&dispcc DISP_CC_MDSS_MDP_CLK>;

			resets = <&dispcc DISP_CC_MDSS_CORE_BCR>;

			power-domains = <&dispcc DISP_CC_MDSS_CORE_GDSC>;

			iommus = <&apps_smmu 0x2800 0x402>;

			interrupt-controller;
			#interrupt-cells = <1>;

			#address-cells = <2>;
			#size-cells = <2>;
			ranges;

			status = "disabled";

			mdss_mdp: display-controller@ae01000 {
				compatible = "qcom,fillmore-dpu";
				reg = <0x0 0x0ae01000 0x0 0x8f000>,
				      <0x0 0x0aeb0000 0x0 0x3000>;
				reg-names = "mdp",
					    "vbif";

				interrupts-extended = <&mdss 0>;

				clocks = <&gcc GCC_DISP_HF_AXI_CLK>,
					 <&gcc GCC_DISP_SF_AXI_CLK>,
					 <&dispcc DISP_CC_MDSS_AHB_CLK>,
					 <&dispcc DISP_CC_MDSS_MDP_LUT_CLK>,
					 <&dispcc DISP_CC_MDSS_MDP_CLK>,
					 <&dispcc DISP_CC_MDSS_VSYNC_CLK>;
				clock-names = "bus",
					      "nrt_bus",
					      "iface",
					      "lut",
					      "core",
					      "vsync";

				assigned-clocks = <&dispcc DISP_CC_MDSS_VSYNC_CLK>;
				assigned-clock-rates = <19200000>;

				operating-points-v2 = <&mdp_opp_table>;

				ports {
					#address-cells = <1>;
					#size-cells = <0>;

					port@0 {
						reg = <0>;

						dpu_intf1_out: endpoint {
							remote-endpoint = <&mdss_dsi0_in>;
						};
					};
				};

				mdp_opp_table: opp-table {
					compatible = "operating-points-v2";

					opp-172000000 {
						opp-hz = /bits/ 64 <172000000>;
						required-opps = <&rpmhpd_opp_low_svs_d1>;
					};

					opp-200000000 {
						opp-hz = /bits/ 64 <200000000>;
						required-opps = <&rpmhpd_opp_low_svs>;
					};

					opp-325000000 {
						opp-hz = /bits/ 64 <325000000>;
						required-opps = <&rpmhpd_opp_svs>;
					};

					opp-375000000 {
						opp-hz = /bits/ 64 <375000000>;
						required-opps = <&rpmhpd_opp_svs_l1>;
					};

					opp-500000000 {
						opp-hz = /bits/ 64 <500000000>;
						required-opps = <&rpmhpd_opp_nom>;
					};
				};
			};

			mdss_dsi0: dsi@ae94000 {
				compatible = "qcom,fillmore-dsi-ctrl",
					     "qcom,sm8450-dsi-ctrl",
					     "qcom,mdss-dsi-ctrl";
				reg = <0x0 0x0ae94000 0x0 0x400>;
				reg-names = "dsi_ctrl";

				interrupts-extended = <&mdss 4>;

				clocks = <&dispcc DISP_CC_MDSS_BYTE0_CLK>,
					 <&dispcc DISP_CC_MDSS_BYTE0_INTF_CLK>,
					 <&dispcc DISP_CC_MDSS_PCLK0_CLK>,
					 <&dispcc DISP_CC_MDSS_ESC0_CLK>,
					 <&dispcc DISP_CC_MDSS_AHB_CLK>,
					 <&gcc GCC_DISP_HF_AXI_CLK>;
				clock-names = "byte",
					      "byte_intf",
					      "pixel",
					      "core",
					      "iface",
					      "bus";

				assigned-clocks = <&dispcc DISP_CC_MDSS_BYTE0_CLK_SRC>,
						  <&dispcc DISP_CC_MDSS_PCLK0_CLK_SRC>;
				assigned-clock-parents = <&mdss_dsi0_phy DSI_BYTE_PLL_CLK>,
							 <&mdss_dsi0_phy DSI_PIXEL_PLL_CLK>;

				operating-points-v2 = <&mdss_dsi_opp_table>;

				phys = <&mdss_dsi0_phy>;
				phy-names = "dsi";

				#address-cells = <1>;
				#size-cells = <0>;

				status = "disabled";

				ports {
					#address-cells = <1>;
					#size-cells = <0>;

					port@0 {
						reg = <0>;

						mdss_dsi0_in: endpoint {
							remote-endpoint = <&dpu_intf1_out>;
						};
					};

					port@1 {
						reg = <1>;

						mdss_dsi0_out: endpoint {
						};
					};
				};

				mdss_dsi_opp_table: opp-table {
					compatible = "operating-points-v2";

					opp-187500000 {
						opp-hz = /bits/ 64 <187500000>;
						required-opps = <&rpmhpd_opp_low_svs>;
					};

					opp-300000000 {
						opp-hz = /bits/ 64 <300000000>;
						required-opps = <&rpmhpd_opp_svs>;
					};

					opp-358000000 {
						opp-hz = /bits/ 64 <358000000>;
						required-opps = <&rpmhpd_opp_svs_l1>;
					};
				};
			};

			mdss_dsi0_phy: phy@ae94400 {
				compatible = "qcom,fillmore-dsi-phy-5nm",
					     "qcom,sm8450-dsi-phy-5nm";
				reg = <0 0x0ae94400 0 0x200>,
				      <0 0x0ae94600 0 0x280>,
				      <0 0x0ae94900 0 0x260>;
				reg-names = "dsi_phy",
					    "dsi_phy_lane",
					    "dsi_pll";

				clocks = <&dispcc DISP_CC_MDSS_AHB_CLK>,
					 <&rpmhcc RPMH_CXO_CLK>;
				clock-names = "iface",
					      "ref";

				#clock-cells = <1>;
				#phy-cells = <0>;

				status = "disabled";
			};
		};

		dispcc: clock-controller@af00000 {
			compatible = "qcom,fillmore-dispcc";
			reg = <0x0 0x0af00000 0x0 0x20000>;

			clocks = <&rpmhcc RPMH_CXO_CLK>,
				 <&rpmhcc RPMH_CXO_CLK_A>,
				 <&gcc GCC_DISP_AHB_CLK>,
				 <&sleep_clk>,
				 <&mdss_dsi0_phy DSI_BYTE_PLL_CLK>,
				 <&mdss_dsi0_phy DSI_PIXEL_PLL_CLK>,
				 <0>, /* dsi1_phy_pll_out_byteclk */
				 <0>, /* dsi1_phy_pll_out_dsiclk */
				 <0>, /* dp0 */
				 <0>,
				 <0>, /* dp1 */
				 <0>,
				 <0>, /* dp2 */
				 <0>,
				 <0>, /* dp3 */
				 <0>;

			power-domains = <&rpmhpd RPMHPD_CX>;

			#clock-cells = <1>;
			#reset-cells = <1>;
			#power-domain-cells = <1>;
		};

		pdc: interrupt-controller@b220000 {
			compatible = "qcom,fillmore-pdc", "qcom,pdc";
			reg = <0x0 0x0b220000 0x0 0x30000>,
			      <0x0 0x174000f0 0x0 0x64>;
			interrupt-parent = <&intc>;

			qcom,pdc-ranges = <0 480 94>, <94 609 31>, <125 63 1>,
					  <126 716 12>;

			#interrupt-cells = <2>;
			interrupt-controller;
		};

		aoss_qmp: power-management@c300000 {
			compatible = "qcom,fillmore-aoss-qmp", "qcom,aoss-qmp";
			reg = <0x0 0x0c300000 0x0 0x400>;

			interrupt-parent = <&ipcc>;
			interrupts-extended = <&ipcc IPCC_CLIENT_AOP IPCC_MPROC_SIGNAL_GLINK_QMP
						     IRQ_TYPE_EDGE_RISING>;

			mboxes = <&ipcc IPCC_CLIENT_AOP IPCC_MPROC_SIGNAL_GLINK_QMP>;

			#clock-cells = <0>;
		};

		sram@c3f0000 {
			compatible = "qcom,rpmh-stats";
			reg = <0x0 0x0c3f0000 0x0 0x400>;
			qcom,qmp = <&aoss_qmp>;
		};

		spmi_bus: spmi@c400000 {
			compatible = "qcom,spmi-pmic-arb";
			reg = <0x0 0x0c400000 0x0 0x3000>,
			      <0x0 0x0c500000 0x0 0x400000>,
			      <0x0 0x0c440000 0x0 0x80000>,
			      <0x0 0x0c4c0000 0x0 0x10000>,
			      <0x0 0x0c42d000 0x0 0x10000>;
			reg-names = "core",
				    "chnls",
				    "obsrvr",
				    "intr",
				    "cnfg";

			interrupts-extended = <&pdc 1 IRQ_TYPE_LEVEL_HIGH>;
			interrupt-names = "periph_irq";

			qcom,ee = <0>;
			qcom,channel = <0>;

			interrupt-controller;
			#interrupt-cells = <4>;

			#address-cells = <2>;
			#size-cells = <0>;
		};

		ipcc: mailbox@ed18000 {
			compatible = "qcom,fillmore-ipcc", "qcom,ipcc";
			reg = <0x0 0x0ed18000 0x0 0x1000>;

			interrupts = <GIC_SPI 229 IRQ_TYPE_LEVEL_HIGH>;

			interrupt-controller;
			#interrupt-cells = <3>;

			#mbox-cells = <2>;
		};

		tlmm: pinctrl@f100000 {
			compatible = "qcom,fillmore-tlmm";
			reg = <0x0 0x0f100000 0x0 0x300000>;

			interrupts = <GIC_SPI 208 IRQ_TYPE_LEVEL_HIGH>;

			gpio-controller;
			#gpio-cells = <2>;

			interrupt-controller;
			#interrupt-cells = <2>;

			gpio-ranges = <&tlmm 0 0 171>;

			wakeup-parent = <&pdc>;

			qup_i2c1_data_clk: qup-i2c1-data-clk-state {
				/* SDA, SCL */
				pins = "gpio4", "gpio5";
				function = "qup0_se1";
				drive-strength = <2>;
				bias-pull-up;
			};

			qup_i2c2_data_clk: qup-i2c2-data-clk-state {
				/* SDA, SCL */
				pins = "gpio8", "gpio9";
				function = "qup0_se2";
				drive-strength = <2>;
				bias-pull-up;
			};

			qup_i2c3_data_clk: qup-i2c3-data-clk-state {
				/* SDA, SCL */
				pins = "gpio12", "gpio13";
				function = "qup0_se3";
				drive-strength = <2>;
				bias-pull-up;
			};

			qup_i2c4_data_clk: qup-i2c4-data-clk-state {
				/* SDA, SCL */
				pins = "gpio16", "gpio17";
				function = "qup0_se4";
				drive-strength = <2>;
				bias-pull-up;
			};

			qup_i2c9_data_clk: qup-i2c9-data-clk-state {
				/* SDA, SCL */
				pins = "gpio36", "gpio37";
				function = "qup1_se1";
				drive-strength = <2>;
				bias-pull-up;
			};

			qup_i2c12_data_clk: qup-i2c12-data-clk-state {
				/* SDA, SCL */
				pins = "gpio48", "gpio49";
				function = "qup1_se4";
				drive-strength = <2>;
				bias-pull-up;
			};

			qup_i2c13_data_clk: qup-i2c13-data-clk-state {
				/* SDA, SCL */
				pins = "gpio52", "gpio53";
				function = "qup1_se5";
				drive-strength = <2>;
				bias-pull-up;
			};

			qup_spi0_cs: qup-spi0-cs-state {
				pins = "gpio3";
				function = "qup0_se0";
				drive-strength = <6>;
				bias-disable;
			};

			qup_spi0_data_clk: qup-spi0-data-clk-state {
				/* MISO, MOSI, CLK */
				pins = "gpio0", "gpio1", "gpio2";
				function = "qup0_se0";
				drive-strength = <6>;
				bias-disable;
			};

			qup_spi11_cs: qup-spi11-cs-state {
				pins = "gpio44";
				function = "qup1_se3";
				drive-strength = <6>;
				bias-disable;
			};

			qup_spi11_data_clk: qup-spi11-data-clk-state {
				/* MISO, MOSI, CLK */
				pins = "gpio45", "gpio46", "gpio47";
				function = "qup1_se3";
				drive-strength = <6>;
				bias-disable;
			};

			qup_uart5_default: qup-uart5-default-state {
				/* TX, RX */
				pins = "gpio22", "gpio23";
				function = "qup0_se5";
				drive-strength = <2>;
				bias-disable;
			};

			qup_uart7_cts: qup-uart7-cts-state {
				pins = "gpio28";
				function = "qup0_se7";
			};

			qup_uart7_rts: qup-uart7-rts-state {
				pins = "gpio29";
				function = "qup0_se7";
			};

			qup_uart7_tx: qup-uart7-tx-state {
				pins = "gpio30";
				function = "qup0_se7";
			};

			qup_uart7_rx: qup-uart7-rx-state {
				pins = "gpio31";
				function = "qup0_se7";
			};
		};

		sram@146aa000 {
			compatible = "qcom,fillmore-imem", "syscon", "simple-mfd";
			reg = <0x0 0x146aa000 0x0 0x1000>;
			ranges = <0 0 0x146aa000 0x1000>;

			#address-cells = <1>;
			#size-cells = <1>;

			pil-reloc@94c {
				compatible = "qcom,pil-reloc-info";
				reg = <0x94c 0xc8>;
			};
		};

		apps_smmu: iommu@15000000 {
			compatible = "qcom,fillmore-smmu-500", "qcom,smmu-500", "arm,mmu-500";
			reg = <0x0 0x15000000 0x0 0x100000>;
			#iommu-cells = <2>;
			#global-interrupts = <1>;
			interrupts = <GIC_SPI 65 IRQ_TYPE_LEVEL_HIGH>,
				     <GIC_SPI 97 IRQ_TYPE_LEVEL_HIGH>,
				     <GIC_SPI 98 IRQ_TYPE_LEVEL_HIGH>,
				     <GIC_SPI 99 IRQ_TYPE_LEVEL_HIGH>,
				     <GIC_SPI 100 IRQ_TYPE_LEVEL_HIGH>,
				     <GIC_SPI 101 IRQ_TYPE_LEVEL_HIGH>,
				     <GIC_SPI 102 IRQ_TYPE_LEVEL_HIGH>,
				     <GIC_SPI 103 IRQ_TYPE_LEVEL_HIGH>,
				     <GIC_SPI 104 IRQ_TYPE_LEVEL_HIGH>,
				     <GIC_SPI 105 IRQ_TYPE_LEVEL_HIGH>,
				     <GIC_SPI 106 IRQ_TYPE_LEVEL_HIGH>,
				     <GIC_SPI 107 IRQ_TYPE_LEVEL_HIGH>,
				     <GIC_SPI 108 IRQ_TYPE_LEVEL_HIGH>,
				     <GIC_SPI 109 IRQ_TYPE_LEVEL_HIGH>,
				     <GIC_SPI 110 IRQ_TYPE_LEVEL_HIGH>,
				     <GIC_SPI 111 IRQ_TYPE_LEVEL_HIGH>,
				     <GIC_SPI 112 IRQ_TYPE_LEVEL_HIGH>,
				     <GIC_SPI 113 IRQ_TYPE_LEVEL_HIGH>,
				     <GIC_SPI 114 IRQ_TYPE_LEVEL_HIGH>,
				     <GIC_SPI 115 IRQ_TYPE_LEVEL_HIGH>,
				     <GIC_SPI 116 IRQ_TYPE_LEVEL_HIGH>,
				     <GIC_SPI 117 IRQ_TYPE_LEVEL_HIGH>,
				     <GIC_SPI 118 IRQ_TYPE_LEVEL_HIGH>,
				     <GIC_SPI 181 IRQ_TYPE_LEVEL_HIGH>,
				     <GIC_SPI 182 IRQ_TYPE_LEVEL_HIGH>,
				     <GIC_SPI 183 IRQ_TYPE_LEVEL_HIGH>,
				     <GIC_SPI 184 IRQ_TYPE_LEVEL_HIGH>,
				     <GIC_SPI 185 IRQ_TYPE_LEVEL_HIGH>,
				     <GIC_SPI 186 IRQ_TYPE_LEVEL_HIGH>,
				     <GIC_SPI 187 IRQ_TYPE_LEVEL_HIGH>,
				     <GIC_SPI 188 IRQ_TYPE_LEVEL_HIGH>,
				     <GIC_SPI 189 IRQ_TYPE_LEVEL_HIGH>,
				     <GIC_SPI 190 IRQ_TYPE_LEVEL_HIGH>,
				     <GIC_SPI 191 IRQ_TYPE_LEVEL_HIGH>,
				     <GIC_SPI 192 IRQ_TYPE_LEVEL_HIGH>,
				     <GIC_SPI 315 IRQ_TYPE_LEVEL_HIGH>,
				     <GIC_SPI 316 IRQ_TYPE_LEVEL_HIGH>,
				     <GIC_SPI 317 IRQ_TYPE_LEVEL_HIGH>,
				     <GIC_SPI 318 IRQ_TYPE_LEVEL_HIGH>,
				     <GIC_SPI 319 IRQ_TYPE_LEVEL_HIGH>,
				     <GIC_SPI 320 IRQ_TYPE_LEVEL_HIGH>,
				     <GIC_SPI 321 IRQ_TYPE_LEVEL_HIGH>,
				     <GIC_SPI 322 IRQ_TYPE_LEVEL_HIGH>,
				     <GIC_SPI 323 IRQ_TYPE_LEVEL_HIGH>,
				     <GIC_SPI 324 IRQ_TYPE_LEVEL_HIGH>,
				     <GIC_SPI 325 IRQ_TYPE_LEVEL_HIGH>,
				     <GIC_SPI 326 IRQ_TYPE_LEVEL_HIGH>,
				     <GIC_SPI 327 IRQ_TYPE_LEVEL_HIGH>,
				     <GIC_SPI 328 IRQ_TYPE_LEVEL_HIGH>,
				     <GIC_SPI 329 IRQ_TYPE_LEVEL_HIGH>,
				     <GIC_SPI 330 IRQ_TYPE_LEVEL_HIGH>,
				     <GIC_SPI 331 IRQ_TYPE_LEVEL_HIGH>,
				     <GIC_SPI 332 IRQ_TYPE_LEVEL_HIGH>,
				     <GIC_SPI 333 IRQ_TYPE_LEVEL_HIGH>,
				     <GIC_SPI 334 IRQ_TYPE_LEVEL_HIGH>,
				     <GIC_SPI 335 IRQ_TYPE_LEVEL_HIGH>,
				     <GIC_SPI 336 IRQ_TYPE_LEVEL_HIGH>,
				     <GIC_SPI 337 IRQ_TYPE_LEVEL_HIGH>,
				     <GIC_SPI 338 IRQ_TYPE_LEVEL_HIGH>,
				     <GIC_SPI 339 IRQ_TYPE_LEVEL_HIGH>,
				     <GIC_SPI 340 IRQ_TYPE_LEVEL_HIGH>,
				     <GIC_SPI 341 IRQ_TYPE_LEVEL_HIGH>,
				     <GIC_SPI 342 IRQ_TYPE_LEVEL_HIGH>,
				     <GIC_SPI 343 IRQ_TYPE_LEVEL_HIGH>,
				     <GIC_SPI 344 IRQ_TYPE_LEVEL_HIGH>,
				     <GIC_SPI 345 IRQ_TYPE_LEVEL_HIGH>,
				     <GIC_SPI 395 IRQ_TYPE_LEVEL_HIGH>,
				     <GIC_SPI 396 IRQ_TYPE_LEVEL_HIGH>,
				     <GIC_SPI 397 IRQ_TYPE_LEVEL_HIGH>,
				     <GIC_SPI 398 IRQ_TYPE_LEVEL_HIGH>,
				     <GIC_SPI 399 IRQ_TYPE_LEVEL_HIGH>,
				     <GIC_SPI 400 IRQ_TYPE_LEVEL_HIGH>,
				     <GIC_SPI 401 IRQ_TYPE_LEVEL_HIGH>,
				     <GIC_SPI 402 IRQ_TYPE_LEVEL_HIGH>,
				     <GIC_SPI 403 IRQ_TYPE_LEVEL_HIGH>,
				     <GIC_SPI 404 IRQ_TYPE_LEVEL_HIGH>,
				     <GIC_SPI 405 IRQ_TYPE_LEVEL_HIGH>,
				     <GIC_SPI 406 IRQ_TYPE_LEVEL_HIGH>,
				     <GIC_SPI 407 IRQ_TYPE_LEVEL_HIGH>,
				     <GIC_SPI 408 IRQ_TYPE_LEVEL_HIGH>,
				     <GIC_SPI 409 IRQ_TYPE_LEVEL_HIGH>,
				     <GIC_SPI 418 IRQ_TYPE_LEVEL_HIGH>,
				     <GIC_SPI 419 IRQ_TYPE_LEVEL_HIGH>,
				     <GIC_SPI 412 IRQ_TYPE_LEVEL_HIGH>,
				     <GIC_SPI 421 IRQ_TYPE_LEVEL_HIGH>,
				     <GIC_SPI 707 IRQ_TYPE_LEVEL_HIGH>,
				     <GIC_SPI 423 IRQ_TYPE_LEVEL_HIGH>,
				     <GIC_SPI 424 IRQ_TYPE_LEVEL_HIGH>,
				     <GIC_SPI 425 IRQ_TYPE_LEVEL_HIGH>,
				     <GIC_SPI 690 IRQ_TYPE_LEVEL_HIGH>,
				     <GIC_SPI 691 IRQ_TYPE_LEVEL_HIGH>,
				     <GIC_SPI 692 IRQ_TYPE_LEVEL_HIGH>,
				     <GIC_SPI 693 IRQ_TYPE_LEVEL_HIGH>,
				     <GIC_SPI 694 IRQ_TYPE_LEVEL_HIGH>,
				     <GIC_SPI 695 IRQ_TYPE_LEVEL_HIGH>,
				     <GIC_SPI 696 IRQ_TYPE_LEVEL_HIGH>,
				     <GIC_SPI 697 IRQ_TYPE_LEVEL_HIGH>;
			dma-coherent;
		};

		intc: interrupt-controller@17100000 {
			compatible = "arm,gic-v3";
			reg = <0x0 0x17100000 0x0 0x10000>,     /* GICD */
			      <0x0 0x17180000 0x0 0x200000>;    /* GICR * 8 */

			interrupts = <GIC_PPI 9 IRQ_TYPE_LEVEL_LOW>;

			#interrupt-cells = <3>;
			interrupt-controller;

			#redistributor-regions = <1>;
			redistributor-stride = <0x0 0x40000>;

			#address-cells = <2>;
			#size-cells = <2>;
			ranges;

			gic_its: msi-controller@17140000 {
				compatible = "arm,gic-v3-its";
				reg = <0x0 0x17140000 0x0 0x20000>;

				msi-controller;
				#msi-cells = <1>;
			};
		};


		wifi: wifi@17110040 {
			compatible = "qcom,wcn6750-wifi";
			reg = <0x0 0x17110040 0x0 0x0>;

			iommus = <&apps_smmu 0x1c00 0x1>;

			interrupts = <GIC_SPI 768 IRQ_TYPE_EDGE_RISING>,
				     <GIC_SPI 769 IRQ_TYPE_EDGE_RISING>,
				     <GIC_SPI 770 IRQ_TYPE_EDGE_RISING>,
				     <GIC_SPI 771 IRQ_TYPE_EDGE_RISING>,
				     <GIC_SPI 772 IRQ_TYPE_EDGE_RISING>,
				     <GIC_SPI 773 IRQ_TYPE_EDGE_RISING>,
				     <GIC_SPI 774 IRQ_TYPE_EDGE_RISING>,
				     <GIC_SPI 775 IRQ_TYPE_EDGE_RISING>,
				     <GIC_SPI 776 IRQ_TYPE_EDGE_RISING>,
				     <GIC_SPI 777 IRQ_TYPE_EDGE_RISING>,
				     <GIC_SPI 778 IRQ_TYPE_EDGE_RISING>,
				     <GIC_SPI 779 IRQ_TYPE_EDGE_RISING>,
				     <GIC_SPI 780 IRQ_TYPE_EDGE_RISING>,
				     <GIC_SPI 781 IRQ_TYPE_EDGE_RISING>,
				     <GIC_SPI 782 IRQ_TYPE_EDGE_RISING>,
				     <GIC_SPI 783 IRQ_TYPE_EDGE_RISING>,
				     <GIC_SPI 784 IRQ_TYPE_EDGE_RISING>,
				     <GIC_SPI 785 IRQ_TYPE_EDGE_RISING>,
				     <GIC_SPI 786 IRQ_TYPE_EDGE_RISING>,
				     <GIC_SPI 787 IRQ_TYPE_EDGE_RISING>,
				     <GIC_SPI 788 IRQ_TYPE_EDGE_RISING>,
				     <GIC_SPI 789 IRQ_TYPE_EDGE_RISING>,
				     <GIC_SPI 790 IRQ_TYPE_EDGE_RISING>,
				     <GIC_SPI 791 IRQ_TYPE_EDGE_RISING>,
				     <GIC_SPI 792 IRQ_TYPE_EDGE_RISING>,
				     <GIC_SPI 793 IRQ_TYPE_EDGE_RISING>,
				     <GIC_SPI 794 IRQ_TYPE_EDGE_RISING>,
				     <GIC_SPI 795 IRQ_TYPE_EDGE_RISING>,
				     <GIC_SPI 796 IRQ_TYPE_EDGE_RISING>,
				     <GIC_SPI 797 IRQ_TYPE_EDGE_RISING>,
				     <GIC_SPI 798 IRQ_TYPE_EDGE_RISING>,
				     <GIC_SPI 799 IRQ_TYPE_EDGE_RISING>;

			memory-region = <&wlan_fw_mem>;

			qcom,rproc = <&remoteproc_wpss>;
			qcom,smem-states = <&smp2p_wlan_out 0>;
			qcom,smem-state-names = "wlan-smp2p-out";

			status = "disabled";
		};

		timer@17420000 {
			compatible = "arm,armv7-timer-mem";
			reg = <0x0 0x17420000 0x0 0x1000>;

			clock-frequency = <19200000>;

			ranges = <0 0 0 0x20000000>;
			#address-cells = <1>;
			#size-cells = <1>;

			frame@17421000 {
				reg = <0x17421000 0x1000>,
				      <0x17422000 0x1000>;

				interrupts = <GIC_SPI 8 IRQ_TYPE_LEVEL_HIGH>,
					     <GIC_SPI 6 IRQ_TYPE_LEVEL_HIGH>;

				frame-number = <0>;
			};

			frame@17423000 {
				reg = <0x17423000 0x1000>;

				interrupts = <GIC_SPI 9 IRQ_TYPE_LEVEL_HIGH>;

				frame-number = <1>;

				status = "disabled";
			};

			frame@17425000 {
				reg = <0x17425000 0x1000>;

				interrupts = <GIC_SPI 10 IRQ_TYPE_LEVEL_HIGH>;

				frame-number = <2>;

				status = "disabled";
			};

			frame@17427000 {
				reg = <0x17427000 0x1000>;

				interrupts = <GIC_SPI 11 IRQ_TYPE_LEVEL_HIGH>;

				frame-number = <3>;

				status = "disabled";
			};

			frame@17429000 {
				reg = <0x17429000 0x1000>;

				interrupts = <GIC_SPI 12 IRQ_TYPE_LEVEL_HIGH>;

				frame-number = <4>;

				status = "disabled";
			};

			frame@1742b000 {
				reg = <0x1742b000 0x1000>;

				interrupts = <GIC_SPI 13 IRQ_TYPE_LEVEL_HIGH>;

				frame-number = <5>;

				status = "disabled";
			};

			frame@1742d000 {
				reg = <0x1742d000 0x1000>;

				interrupts = <GIC_SPI 14 IRQ_TYPE_LEVEL_HIGH>;

				frame-number = <6>;

				status = "disabled";
			};
		};

		apps_rsc: rsc@17a00000 {
			compatible = "qcom,rpmh-rsc";
			reg = <0x0 0x17a00000 0x0 0x10000>,
			      <0x0 0x17a10000 0x0 0x10000>,
			      <0x0 0x17a20000 0x0 0x10000>;
			reg-names = "drv-0",
				    "drv-1",
				    "drv-2";

			interrupts = <GIC_SPI 3 IRQ_TYPE_LEVEL_HIGH>,
				     <GIC_SPI 4 IRQ_TYPE_LEVEL_HIGH>,
				     <GIC_SPI 5 IRQ_TYPE_LEVEL_HIGH>;

			power-domains = <&cluster_pd>;

			qcom,tcs-offset = <0xd00>;
			qcom,drv-id = <2>;
			qcom,tcs-config = <ACTIVE_TCS  3>, <SLEEP_TCS   2>,
					  <WAKE_TCS    2>, <CONTROL_TCS 0>;

			label = "apps_rsc";

			apps_bcm_voter: bcm-voter {
				compatible = "qcom,bcm-voter";
			};

			rpmhcc: clock-controller {
				compatible = "qcom,fillmore-rpmh-clk";

				clocks = <&xo_board>;
				clock-names = "xo";

				#clock-cells = <1>;
			};

			rpmhpd: power-controller {
				compatible = "qcom,fillmore-rpmhpd", "qcom,sm8450-rpmhpd";

				operating-points-v2 = <&rpmhpd_opp_table>;

				#power-domain-cells = <1>;

				rpmhpd_opp_table: opp-table {
					compatible = "operating-points-v2";

					rpmhpd_opp_ret: opp1 {
						opp-level = <RPMH_REGULATOR_LEVEL_RETENTION>;
					};

					rpmhpd_opp_min_svs: opp2 {
						opp-level = <RPMH_REGULATOR_LEVEL_MIN_SVS>;
					};

					rpmhpd_opp_low_svs_d1: opp3 {
						opp-level = <RPMH_REGULATOR_LEVEL_LOW_SVS_D1>;
					};

					rpmhpd_opp_low_svs: opp4 {
						opp-level = <RPMH_REGULATOR_LEVEL_LOW_SVS>;
					};

					rpmhpd_opp_low_svs_l1: opp5 {
						opp-level = <RPMH_REGULATOR_LEVEL_LOW_SVS_L1>;
					};

					rpmhpd_opp_svs: opp6 {
						opp-level = <RPMH_REGULATOR_LEVEL_SVS>;
					};

					rpmhpd_opp_svs_l0: opp7 {
						opp-level = <RPMH_REGULATOR_LEVEL_SVS_L0>;
					};

					rpmhpd_opp_svs_l1: opp8 {
						opp-level = <RPMH_REGULATOR_LEVEL_SVS_L1>;
					};

					rpmhpd_opp_svs_l2: opp9 {
						opp-level = <RPMH_REGULATOR_LEVEL_SVS_L2>;
					};

					rpmhpd_opp_nom: opp10 {
						opp-level = <RPMH_REGULATOR_LEVEL_NOM>;
					};

					rpmhpd_opp_nom_l1: opp11 {
						opp-level = <RPMH_REGULATOR_LEVEL_NOM_L1>;
					};

					rpmhpd_opp_nom_l2: opp12 {
						opp-level = <RPMH_REGULATOR_LEVEL_NOM_L2>;
					};

					rpmhpd_opp_turbo: opp13 {
						opp-level = <RPMH_REGULATOR_LEVEL_TURBO>;
					};

					rpmhpd_opp_turbo_l1: opp14 {
						opp-level = <RPMH_REGULATOR_LEVEL_TURBO_L1>;
					};
				};
			};
		};

		cpufreq_hw: cpufreq@17d91000 {
			compatible = "qcom,fillmore-cpufreq-epss", "qcom,cpufreq-epss";
			reg = <0x0 0x17d91000 0x0 0x1000>,
			      <0x0 0x17d92000 0x0 0x1000>,
			      <0x0 0x17d93000 0x0 0x1000>;
			reg-names = "freq-domain0",
				    "freq-domain1",
				    "freq-domain2";

			interrupts = <GIC_SPI 30 IRQ_TYPE_LEVEL_HIGH>,
				     <GIC_SPI 31 IRQ_TYPE_LEVEL_HIGH>,
				     <GIC_SPI 19 IRQ_TYPE_LEVEL_HIGH>;
			interrupt-names = "dcvsh-irq-0",
					  "dcvsh-irq-1",
					  "dcvsh-irq-2";

			clocks = <&rpmhcc RPMH_CXO_CLK>,
				 <&gcc GCC_GPLL0>;
			clock-names = "xo",
				      "alternate";

			#freq-domain-cells = <1>;
			#clock-cells = <1>;
		};

		qfprom: efuse@221c8000 {
			compatible = "qcom,fillmore-qfprom", "qcom,qfprom";
			reg = <0 0x221c8000 0 0x1000>;
			#address-cells = <1>;
			#size-cells = <1>;

			gpu_speed_bin: gpu-speed-bin@119 {
				reg = <0x119 0x2>;
				bits = <5 8>;
			};
		};

		remoteproc_cdsp: remoteproc@32300000 {
			compatible = "qcom,fillmore-cdsp-pas";
			reg = <0x0 0x32300000 0x0 0x10000>;

			interrupts-extended = <&intc GIC_SPI 578 IRQ_TYPE_EDGE_RISING>,
					      <&smp2p_cdsp_in 0 IRQ_TYPE_EDGE_RISING>,
					      <&smp2p_cdsp_in 1 IRQ_TYPE_EDGE_RISING>,
					      <&smp2p_cdsp_in 2 IRQ_TYPE_EDGE_RISING>,
					      <&smp2p_cdsp_in 3 IRQ_TYPE_EDGE_RISING>,
					      <&smp2p_cdsp_in 7 IRQ_TYPE_EDGE_RISING>;
			interrupt-names = "wdog",
					  "fatal",
					  "ready",
					  "handover",
					  "stop-ack",
					  "shutdown-ack";

			clocks = <&rpmhcc RPMH_CXO_CLK>;
			clock-names = "xo";

			power-domains = <&rpmhpd RPMHPD_CX>,
					<&rpmhpd RPMHPD_MXC>;
			power-domain-names = "cx",
					     "mxc";

			memory-region = <&cdsp_mem>;

			qcom,qmp = <&aoss_qmp>;

			qcom,smem-states = <&smp2p_cdsp_out 0>;
			qcom,smem-state-names = "stop";

			status = "disabled";

			glink-edge {
				interrupts-extended = <&ipcc IPCC_CLIENT_CDSP
							     IPCC_MPROC_SIGNAL_GLINK_QMP
							     IRQ_TYPE_EDGE_RISING>;
				mboxes = <&ipcc IPCC_CLIENT_CDSP
						IPCC_MPROC_SIGNAL_GLINK_QMP>;

				label = "cdsp";
				qcom,remote-pid = <5>;
			};
		};
	};

	thermal_zones: thermal-zones { };

	timer {
		compatible = "arm,armv8-timer";

		interrupts = <GIC_PPI 13 IRQ_TYPE_LEVEL_LOW>,
			     <GIC_PPI 14 IRQ_TYPE_LEVEL_LOW>,
			     <GIC_PPI 11 IRQ_TYPE_LEVEL_LOW>,
			     <GIC_PPI 12 IRQ_TYPE_LEVEL_LOW>;

		clock-frequency = <19200000>;
	};
};
